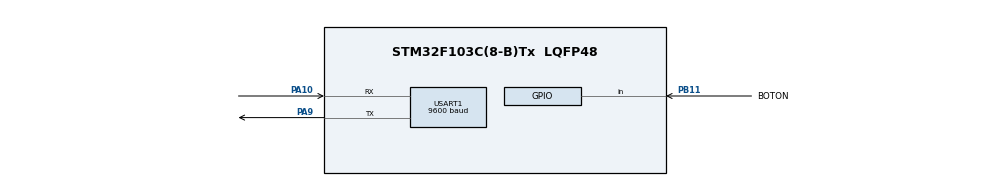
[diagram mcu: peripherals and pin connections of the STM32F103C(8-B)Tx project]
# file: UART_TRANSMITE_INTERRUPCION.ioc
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Mcu.Family=STM32F1
RCC.APB2Freq_Value=8000000
PA10.Mode=Asynchronous
PA14.Mode=Serial_Wire
USART1.BaudRate=9600
PB11.GPIO_Label=BOTON
PA13.Mode=Serial_Wire
Mcu.Name=STM32F103C(8-B)Tx
PB11.Signal=GPIO_Input
Mcu.Package=LQFP48
ProjectManager.StackSize=0x400
PA13.Signal=SYS_JTMS-SWDIO
USART1.VirtualMode=VM_ASYNC
PA9.Mode=Asynchronous
PA10.Signal=USART1_RX
PA14.Signal=SYS_JTCK-SWCLK
ProjectManager.HeapSize=0x200
ProjectManager.TargetToolchain=STM32CubeIDE
NVIC.PriorityGroup=NVIC_PRIORITYGROUP_4
PA9.Signal=USART1_TX
NVIC.USART1_IRQn=true\:0\:0\:false\:false\:true\:true\:true
RCC.APB1Freq_Value=8000000
board=custom

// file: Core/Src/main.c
/* USER CODE BEGIN Header */
/**
  ******************************************************************************
  * @file           : main.c
  * @brief          : Main program body
  ******************************************************************************
  * @attention
  *
  * <h2><center>&copy; Copyright (c) 2023 STMicroelectronics.
  * All rights reserved.</center></h2>
  *
  * This software component is licensed by ST under BSD 3-Clause license,
  * the "License"; You may not use this file except in compliance with the
  * License. You may obtain a copy of the License at:
  *                        opensource.org/licenses/BSD-3-Clause
  *
  ******************************************************************************
  */
/* USER CODE END Header */
#include "main.h"

/* USER CODE BEGIN Includes */
uint8_t transmitir [1];
/* USER CODE END Includes */

UART_HandleTypeDef huart1;

void SystemClock_Config(void);
static void MX_GPIO_Init(void);
static void MX_USART1_UART_Init(void);

int main(void)
{

  /* MCU Configuration--------------------------------------------------------*/

  /* Reset of all peripherals, Initializes the Flash interface and the Systick. */
  HAL_Init();

  /* Configure the system clock */
  SystemClock_Config();

  /* Initialize all configured peripherals */
  MX_GPIO_Init();
  MX_USART1_UART_Init();

  /* Infinite loop */
  while (1)
  {

    /* USER CODE BEGIN 3 */

	 if(HAL_GPIO_ReadPin(GPIOB, BOTON_Pin) == 1){

		 transmitir[0] = 48;
	 }else{
		 transmitir[0] = 49;
	 }

	 HAL_UART_Transmit_IT(&huart1, transmitir, 1);
	 HAL_Delay(500);

  }
  /* USER CODE END 3 */
}

void SystemClock_Config(void)
{
  RCC_OscInitTypeDef RCC_OscInitStruct = {0};
  RCC_ClkInitTypeDef RCC_ClkInitStruct = {0};

  /** Initializes the RCC Oscillators according to the specified parameters
  * in the RCC_OscInitTypeDef structure.
  */
  RCC_OscInitStruct.OscillatorType = RCC_OSCILLATORTYPE_HSI;
  RCC_OscInitStruct.HSIState = RCC_HSI_ON;
  RCC_OscInitStruct.HSICalibrationValue = RCC_HSICALIBRATION_DEFAULT;
  RCC_OscInitStruct.PLL.PLLState = RCC_PLL_NONE;
  if (HAL_RCC_OscConfig(&RCC_OscInitStruct) != HAL_OK)
  {
    Error_Handler();
  }
  /** Initializes the CPU, AHB and APB buses clocks
  */
  RCC_ClkInitStruct.ClockType = RCC_CLOCKTYPE_HCLK|RCC_CLOCKTYPE_SYSCLK
                              |RCC_CLOCKTYPE_PCLK1|RCC_CLOCKTYPE_PCLK2;
  RCC_ClkInitStruct.SYSCLKSource = RCC_SYSCLKSOURCE_HSI;
  RCC_ClkInitStruct.AHBCLKDivider = RCC_SYSCLK_DIV1;
  RCC_ClkInitStruct.APB1CLKDivider = RCC_HCLK_DIV1;
  RCC_ClkInitStruct.APB2CLKDivider = RCC_HCLK_DIV1;

  if (HAL_RCC_ClockConfig(&RCC_ClkInitStruct, FLASH_LATENCY_0) != HAL_OK)
  {
    Error_Handler();
  }
}

static void MX_USART1_UART_Init(void)
{

  huart1.Instance = USART1;
  huart1.Init.BaudRate = 9600;
  huart1.Init.WordLength = UART_WORDLENGTH_8B;
  huart1.Init.StopBits = UART_STOPBITS_1;
  huart1.Init.Parity = UART_PARITY_NONE;
  huart1.Init.Mode = UART_MODE_TX_RX;
  huart1.Init.HwFlowCtl = UART_HWCONTROL_NONE;
  huart1.Init.OverSampling = UART_OVERSAMPLING_16;
  if (HAL_UART_Init(&huart1) != HAL_OK)
  {
    Error_Handler();
  }

}

static void MX_GPIO_Init(void)
{
  GPIO_InitTypeDef GPIO_InitStruct = {0};

  /* GPIO Ports Clock Enable */
  __HAL_RCC_GPIOB_CLK_ENABLE();
  __HAL_RCC_GPIOA_CLK_ENABLE();

  /*Configure GPIO pin : BOTON_Pin */
  GPIO_InitStruct.Pin = BOTON_Pin;
  GPIO_InitStruct.Mode = GPIO_MODE_INPUT;
  GPIO_InitStruct.Pull = GPIO_NOPULL;
  HAL_GPIO_Init(BOTON_GPIO_Port, &GPIO_InitStruct);

}

void Error_Handler(void)
{
  __disable_irq();
  while (1)
  {
  }
}

/************************ (C) COPYRIGHT STMicroelectronics *****END OF FILE****/
